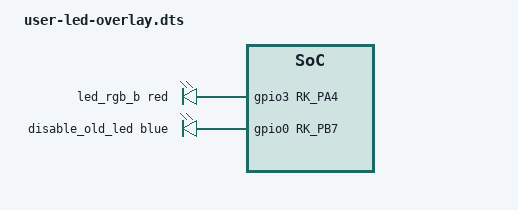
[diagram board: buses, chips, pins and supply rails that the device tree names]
/*
 * Copyright (C) 2022 Mercadian Systems LLC
 */
 
/dts-v1/;
/plugin/;

#include <dt-bindings/gpio/gpio.h>
#include <dt-bindings/leds/common.h>
#include <dt-bindings/pwm/pwm.h>
#include <dt-bindings/pinctrl/rockchip.h>
#include <dt-bindings/input/rk-input.h>

// Overwrites the GPIO pin used for the User LED and the default trigger.
/ {
	fragment@0 {
		target-path = "/";
		__overlay__ {
			leds {
				compatible = "gpio-leds";
				pinctrl-names = "default";
				pinctrl-0 = <&led_rgb_b>;

				led_rgb_b {
					function = LED_FUNCTION_STATUS;
					color = <LED_COLOR_ID_RED>;
					gpios = <&gpio3 RK_PA4 GPIO_ACTIVE_HIGH>; // GPIO3_A4, which is pin 16 (GPIO 100)
					linux,default-trigger = "activity";
				};

				disable_old_led {
					function = LED_FUNCTION_STATUS;
					color = <LED_COLOR_ID_BLUE>;
					gpios = <&gpio0 RK_PB7 GPIO_ACTIVE_HIGH>; // Inbuilt blue user LED on GPIO0_B7, which is not on the GPIO header
					linux,default-trigger = "none";
				};
			};
		};
	};

	fragment@1 {
		target = <&pinctrl>;
		__overlay__ {
			leds {
				led_rgb_b: led-rgb-b {
					rockchip,pins = <3 RK_PA4 RK_FUNC_GPIO &pcfg_pull_none>;
				};

				disable_old_led: disable-old-led {
					rockchip,pins = <0 RK_PB7 RK_FUNC_GPIO &pcfg_pull_down>;
				};
			};
		};
	};
};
